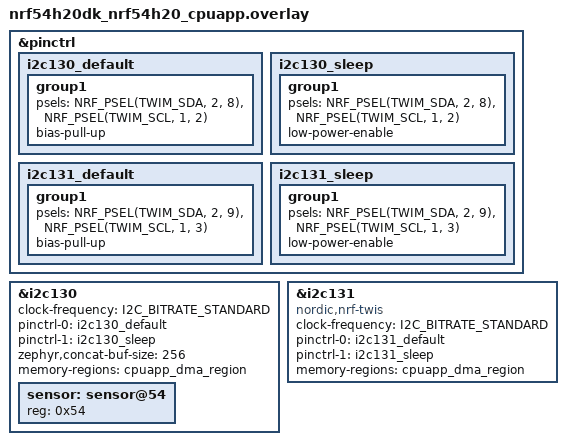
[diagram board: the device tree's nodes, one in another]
/*
 * Copyright (c) 2026 Nordic Semiconductor ASA
 *
 * SPDX-License-Identifier: Apache-2.0
 */

&pinctrl {
	i2c130_default: i2c130_default {
		group1 {
			psels = <NRF_PSEL(TWIM_SDA, 2, 8)>,
				<NRF_PSEL(TWIM_SCL, 1, 2)>;
			bias-pull-up;
		};
	};

	i2c130_sleep: i2c130_sleep {
		group1 {
			psels = <NRF_PSEL(TWIM_SDA, 2, 8)>,
				<NRF_PSEL(TWIM_SCL, 1, 2)>;
			low-power-enable;
		};
	};

	i2c131_default: i2c131_default {
		group1 {
			psels = <NRF_PSEL(TWIM_SDA, 2, 9)>,
				<NRF_PSEL(TWIM_SCL, 1, 3)>;
			bias-pull-up;
		};
	};

	i2c131_sleep: i2c131_sleep {
		group1 {
			psels = <NRF_PSEL(TWIM_SDA, 2, 9)>,
				<NRF_PSEL(TWIM_SCL, 1, 3)>;
			low-power-enable;
		};
	};
};

dut_twim: &i2c130 {
	clock-frequency = <I2C_BITRATE_STANDARD>;
	pinctrl-0 = <&i2c130_default>;
	pinctrl-1 = <&i2c130_sleep>;
	pinctrl-names = "default", "sleep";
	zephyr,concat-buf-size = <256>;
	memory-regions = <&cpuapp_dma_region>;
	status = "okay";

	sensor: sensor@54 {
		reg = <0x54>;
	};
};

dut_twis: &i2c131 {
	compatible = "nordic,nrf-twis";
	clock-frequency = <I2C_BITRATE_STANDARD>;
	pinctrl-0 = <&i2c131_default>;
	pinctrl-1 = <&i2c131_sleep>;
	pinctrl-names = "default", "sleep";
	memory-regions = <&cpuapp_dma_region>;
	status = "okay";
};
